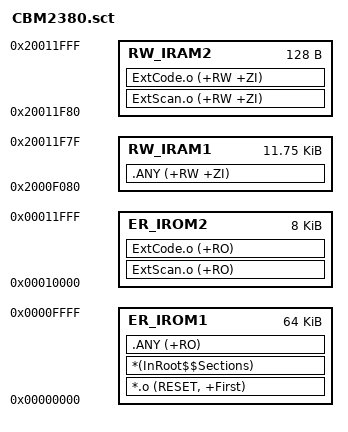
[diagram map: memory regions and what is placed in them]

; *************************************************************
; *** Scatter-Loading Description File generated by uVision ***
; *************************************************************
LR_IROM2 0x00010000 0x00002000  {
  ER_IROM2 0x00010000 0x00002000  {  ; load address = execution address
    ExtScan.o (+RO)
	ExtCode.o (+RO)
  }
  RW_IRAM2 0x20011F80 0x00000080  {
    ExtScan.o (+RW +ZI)
	ExtCode.o (+RW +ZI)
  }
}

LR_IROM1 0x00000000 0x00010000  {    ; load region size_region
  ER_IROM1 0x00000000 0x00010000  {  ; load address = execution address
   *.o (RESET, +First)
   *(InRoot$$Sections)
   .ANY (+RO)
  }
  
  RW_IRAM1 0x2000F080 0x00002F00  {  ; RW data
   .ANY (+RW +ZI)
  }
  
}

